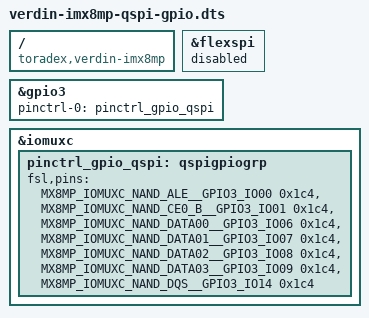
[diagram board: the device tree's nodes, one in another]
/dts-v1/;
/plugin/;

#include "dt-bindings/gpio/gpio.h"
#include "imx8mp-pinfunc.h"

/ {
	compatible = "toradex,verdin-imx8mp";
};

&flexspi {
	status = "disabled";
};

&gpio3 {
	pinctrl-names = "default";
	pinctrl-0 = <&pinctrl_gpio_qspi>;
};

&iomuxc {
	pinctrl_gpio_qspi: qspigpiogrp {
		fsl,pins =
			<MX8MP_IOMUXC_NAND_ALE__GPIO3_IO00		0x1c4>,	// GPIO_SODIMM_52	52	GPIO3_IO0	ALT5	NAND_ALE
			<MX8MP_IOMUXC_NAND_CE0_B__GPIO3_IO01	0x1c4>,	// GPIO_SODIMM_54	54	GPIO3_IO1	ALT5	NAND_CE0_B
			<MX8MP_IOMUXC_NAND_DATA00__GPIO3_IO06	0x1c4>,	// GPIO_SODIMM_56	56	GPIO3_IO6	ALT5	NAND_DATA00
			<MX8MP_IOMUXC_NAND_DATA01__GPIO3_IO07	0x1c4>,	// GPIO_SODIMM_58	58	GPIO3_IO7	ALT5	NAND_DATA01
			<MX8MP_IOMUXC_NAND_DATA02__GPIO3_IO08	0x1c4>,	// GPIO_SODIMM_60	60	GPIO3_IO8	ALT5	NAND_DATA02
			<MX8MP_IOMUXC_NAND_DATA03__GPIO3_IO09	0x1c4>,	// GPIO_SODIMM_62	62	GPIO3_IO9	ALT5	NAND_DATA03
			<MX8MP_IOMUXC_NAND_DQS__GPIO3_IO14		0x1c4>;	// GPIO_SODIMM_66	66	GPIO3_IO14	ALT5	NAND_DQS
	};
};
